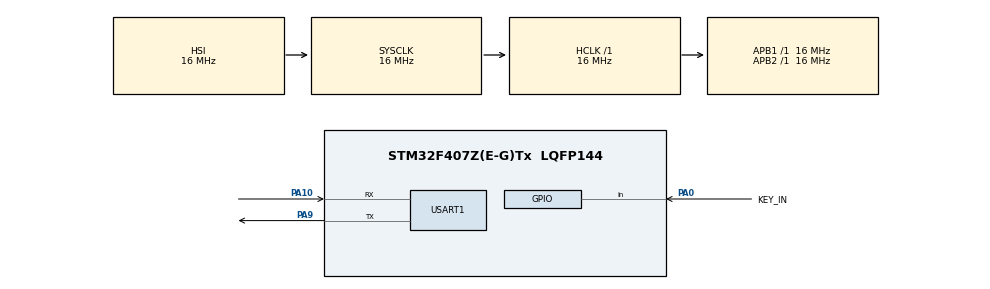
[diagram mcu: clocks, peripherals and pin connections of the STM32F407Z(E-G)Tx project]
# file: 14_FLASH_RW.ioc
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Mcu.Family=STM32F4
Mcu.Name=STM32F407Z(E-G)Tx
Mcu.Package=LQFP144
NVIC.PriorityGroup=NVIC_PRIORITYGROUP_4
PA0-WKUP.GPIO_Label=KEY_IN
PA0-WKUP.GPIO_PuPd=GPIO_PULLDOWN
PA0-WKUP.Signal=GPIO_Input
PA10.Mode=Asynchronous
PA10.Signal=USART1_RX
PA9.Mode=Asynchronous
PA9.Signal=USART1_TX
ProjectManager.HeapSize=0x200
ProjectManager.StackSize=0x400
ProjectManager.TargetToolchain=MDK-ARM V5
RCC.AHBFreq_Value=16000000
RCC.APB1Freq_Value=16000000
RCC.APB2Freq_Value=16000000
RCC.CortexFreq_Value=16000000
RCC.HSE_VALUE=25000000
RCC.HSI_VALUE=16000000
RCC.LSE_VALUE=32768
RCC.SYSCLKFreq_VALUE=16000000
RCC.VCOOutputFreq_Value=192000000
USART1.VirtualMode=VM_ASYNC
board=custom

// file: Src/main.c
/* USER CODE BEGIN Header */
/**
  ******************************************************************************
  * @file           : main.c
  * @brief          : Main program body
  ******************************************************************************
  * @attention
  *
  * <h2><center>&copy; Copyright (c) 2019 STMicroelectronics.
  * All rights reserved.</center></h2>
  *
  * This software component is licensed by ST under BSD 3-Clause license,
  * the "License"; You may not use this file except in compliance with the
  * License. You may obtain a copy of the License at:
  *                        opensource.org/licenses/BSD-3-Clause
  *
  ******************************************************************************
  */
/* USER CODE END Header */

#include "main.h"

UART_HandleTypeDef huart1;

/* USER CODE BEGIN PV */
#define ADDR_FLASH_SECTOR_0     ((uint32_t)0x08000000) /* Base @ of Sector 0, 16 Kbytes */
#define ADDR_FLASH_SECTOR_1     ((uint32_t)0x08004000) /* Base @ of Sector 1, 16 Kbytes */
#define ADDR_FLASH_SECTOR_2     ((uint32_t)0x08008000) /* Base @ of Sector 2, 16 Kbytes */
#define ADDR_FLASH_SECTOR_3     ((uint32_t)0x0800C000) /* Base @ of Sector 3, 16 Kbytes */
#define ADDR_FLASH_SECTOR_4     ((uint32_t)0x08010000) /* Base @ of Sector 4, 64 Kbytes */
#define ADDR_FLASH_SECTOR_5     ((uint32_t)0x08020000) /* Base @ of Sector 5, 128 Kbytes */
#define ADDR_FLASH_SECTOR_6     ((uint32_t)0x08040000) /* Base @ of Sector 6, 128 Kbytes */
#define ADDR_FLASH_SECTOR_7     ((uint32_t)0x08060000) /* Base @ of Sector 7, 128 Kbytes */
#define ADDR_FLASH_SECTOR_8     ((uint32_t)0x08080000) /* Base @ of Sector 8, 128 Kbytes */
#define ADDR_FLASH_SECTOR_9     ((uint32_t)0x080A0000) /* Base @ of Sector 9, 128 Kbytes */
#define ADDR_FLASH_SECTOR_10    ((uint32_t)0x080C0000) /* Base @ of Sector 10, 128 Kbytes */
#define ADDR_FLASH_SECTOR_11    ((uint32_t)0x080E0000) /* Base @ of Sector 11, 128 Kbytes */

#define FLASH_SECTORO_SIZE		((uint32_t)0x04000)
#define FLASH_SECTOR1_SIZE		((uint32_t)0x04000)
#define FLASH_SECTOR2_SIZE		((uint32_t)0x04000)
#define FLASH_SECTOR3_SIZE		((uint32_t)0x04000)
#define FLASH_SECTOR4_SIZE		((uint32_t)0x10000)
#define FLASH_SECTOR5_SIZE		((uint32_t)0x20000)
#define FLASH_SECTOR6_SIZE		((uint32_t)0x20000)
#define FLASH_SECTOR7_SIZE		((uint32_t)0x20000)
#define FLASH_SECTOR8_SIZE		((uint32_t)0x20000)
#define FLASH_SECTOR9_SIZE		((uint32_t)0x20000)
#define FLASH_SECTOR1O_SIZE		((uint32_t)0x20000)
#define FLASH_SECTOR11_SIZE		((uint32_t)0x20000)

const uint8_t data_flash[FLASH_SECTOR2_SIZE] __attribute__((at(ADDR_FLASH_SECTOR_2))) = {
	0x00, 0x11, 0x22, 0x33, 0x44, 0x55, 0x66, 0x77, 0x88, 0x99, 0xAA, 0xBB, 0xCC, 0xDD, 0xEE, 0xFF,
	0x00, 0x11, 0x22, 0x33, 0x44, 0x55, 0x66, 0x77, 0x88, 0x99, 0xAA, 0xBB, 0xCC, 0xDD, 0xEE, 0xFF

};
/* USER CODE END PV */

void SystemClock_Config(void);
static void MX_GPIO_Init(void);
static void MX_USART1_UART_Init(void);
/* USER CODE BEGIN PFP */

HAL_StatusTypeDef flash_write_sector2(uint32_t dat)
{
	FLASH_EraseInitTypeDef EraseInitStruct;
	uint32_t FirstSector = 0, NbOfSectors = 0, Address = 0;
	uint32_t SectorError = 0;

	HAL_FLASH_Unlock();

	FirstSector =  FLASH_SECTOR_2;
	NbOfSectors = 1;

	EraseInitStruct.TypeErase = FLASH_TYPEERASE_SECTORS;
	EraseInitStruct.VoltageRange = FLASH_VOLTAGE_RANGE_3;
	EraseInitStruct.Sector = FirstSector;
	EraseInitStruct.NbSectors = NbOfSectors;
	if(HAL_FLASHEx_Erase(&EraseInitStruct, &SectorError) != HAL_OK)
	{
       	HAL_FLASH_Lock();
		return HAL_ERROR;
	}

  __HAL_FLASH_DATA_CACHE_DISABLE();
  __HAL_FLASH_INSTRUCTION_CACHE_DISABLE();

  __HAL_FLASH_DATA_CACHE_RESET();
  __HAL_FLASH_INSTRUCTION_CACHE_RESET();

  __HAL_FLASH_INSTRUCTION_CACHE_ENABLE();
  __HAL_FLASH_DATA_CACHE_ENABLE();

  /* Program the user Flash area word by word
	(area defined by FLASH_USER_START_ADDR and FLASH_USER_END_ADDR) ***********/

  Address = ADDR_FLASH_SECTOR_2;

	while (Address < ADDR_FLASH_SECTOR_3)
  {
    if (HAL_FLASH_Program(FLASH_TYPEPROGRAM_WORD, Address, dat) == HAL_OK)
    {
      Address = Address + 4;
    }
    else
    {
       	HAL_FLASH_Lock();
        return HAL_ERROR;
    }
  }

  /* Lock the Flash to disable the flash control register access (recommended
     to protect the FLASH memory against possible unwanted operation) *********/
	HAL_FLASH_Lock();
	return  HAL_OK;
}

void flash_read_sector2(void)
{
	uint32_t Address = 0;
	uint32_t data32 = 0;

	Address =  ADDR_FLASH_SECTOR_2;

	while (Address < ADDR_FLASH_SECTOR_3)
	{
		if (0 == (Address%32))
		{
			printf("\r\n");
		}
		data32 = *(__IO uint32_t*)Address;
		printf("0x%08X, ",data32);
		Address = Address + 4;
	}
	printf("\r\n\r\n");
}
/* USER CODE END PFP */

int main(void)
{

  /* MCU Configuration--------------------------------------------------------*/

  /* Reset of all peripherals, Initializes the Flash interface and the Systick. */
  HAL_Init();

  /* Configure the system clock */
  SystemClock_Config();

  /* Initialize all configured peripherals */
  MX_GPIO_Init();
  MX_USART1_UART_Init();

  /* Infinite loop */
  while (1)
  {

    /* USER CODE BEGIN 3 */
	if (GPIO_PIN_SET == HAL_GPIO_ReadPin(KEY_IN_GPIO_Port, KEY_IN_Pin))
	{
		HAL_Delay(20);
		if (GPIO_PIN_SET == HAL_GPIO_ReadPin(KEY_IN_GPIO_Port, KEY_IN_Pin))
		{
			flash_read_sector2();
			flash_write_sector2(0x12345678);
			flash_read_sector2();
			flash_write_sector2(0x89ABCDEF);
			flash_read_sector2();

		}

	}
  }
  /* USER CODE END 3 */
}

void SystemClock_Config(void)
{
  RCC_OscInitTypeDef RCC_OscInitStruct = {0};
  RCC_ClkInitTypeDef RCC_ClkInitStruct = {0};

  /** Configure the main internal regulator output voltage
  */
  __HAL_RCC_PWR_CLK_ENABLE();
  __HAL_PWR_VOLTAGESCALING_CONFIG(PWR_REGULATOR_VOLTAGE_SCALE1);
  /** Initializes the CPU, AHB and APB busses clocks
  */
  RCC_OscInitStruct.OscillatorType = RCC_OSCILLATORTYPE_HSI;
  RCC_OscInitStruct.HSIState = RCC_HSI_ON;
  RCC_OscInitStruct.HSICalibrationValue = RCC_HSICALIBRATION_DEFAULT;
  RCC_OscInitStruct.PLL.PLLState = RCC_PLL_NONE;
  if (HAL_RCC_OscConfig(&RCC_OscInitStruct) != HAL_OK)
  {
    Error_Handler();
  }
  /** Initializes the CPU, AHB and APB busses clocks
  */
  RCC_ClkInitStruct.ClockType = RCC_CLOCKTYPE_HCLK|RCC_CLOCKTYPE_SYSCLK
                              |RCC_CLOCKTYPE_PCLK1|RCC_CLOCKTYPE_PCLK2;
  RCC_ClkInitStruct.SYSCLKSource = RCC_SYSCLKSOURCE_HSI;
  RCC_ClkInitStruct.AHBCLKDivider = RCC_SYSCLK_DIV1;
  RCC_ClkInitStruct.APB1CLKDivider = RCC_HCLK_DIV1;
  RCC_ClkInitStruct.APB2CLKDivider = RCC_HCLK_DIV1;

  if (HAL_RCC_ClockConfig(&RCC_ClkInitStruct, FLASH_LATENCY_0) != HAL_OK)
  {
    Error_Handler();
  }
}

static void MX_USART1_UART_Init(void)
{

  huart1.Instance = USART1;
  huart1.Init.BaudRate = 115200;
  huart1.Init.WordLength = UART_WORDLENGTH_8B;
  huart1.Init.StopBits = UART_STOPBITS_1;
  huart1.Init.Parity = UART_PARITY_NONE;
  huart1.Init.Mode = UART_MODE_TX_RX;
  huart1.Init.HwFlowCtl = UART_HWCONTROL_NONE;
  huart1.Init.OverSampling = UART_OVERSAMPLING_16;
  if (HAL_UART_Init(&huart1) != HAL_OK)
  {
    Error_Handler();
  }

}

static void MX_GPIO_Init(void)
{
  GPIO_InitTypeDef GPIO_InitStruct = {0};

  /* GPIO Ports Clock Enable */
  __HAL_RCC_GPIOA_CLK_ENABLE();

  /*Configure GPIO pin : KEY_IN_Pin */
  GPIO_InitStruct.Pin = KEY_IN_Pin;
  GPIO_InitStruct.Mode = GPIO_MODE_INPUT;
  GPIO_InitStruct.Pull = GPIO_PULLDOWN;
  HAL_GPIO_Init(KEY_IN_GPIO_Port, &GPIO_InitStruct);

}

/* USER CODE BEGIN 4 */
int fputc(int ch, FILE *f)
{
	HAL_UART_Transmit(&huart1, (uint8_t*)&ch, 1, 10);
	return ch;
}
/* USER CODE END 4 */

void Error_Handler(void)
{
}

/************************ (C) COPYRIGHT STMicroelectronics *****END OF FILE****/
